# A31G12x register map
Vendor: VENDOR ABOV Semiconductor Co., Ltd.; Series: A31G12x; File version: 1.0
CPU: CM0+ r0p1, little endian, no MPU, no FPU, VTOR, 2 interrupt priority bits
Registers are 32-bit, read-write, reset 0x0 unless marked. A register's access mark holds for its fields unless they carry their own. Offsets are from the block's base; [hi:lo] are bit positions; {n}, {i} and the like mark numbered series.

## ADC — 12 Bit A/D Converter
Base 0x40003000
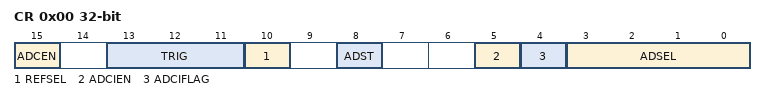
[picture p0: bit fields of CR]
0x00 CR — A/D Converter Control Register
  [15] ADCEN — ADC Module Enable
    0=Disable ADC module operation; 1=Enable ADC module operation
  [13:11] TRIG — ADC Trigger Signal Selection
    0=ADST (Select ADST.); 1=TIMER10 (Select TIMER10 A-Match Signal.); 2=TIMER11 (Select TIMER11 A-Match Signal.); 3=TIMER12 (Select TIMER12 A-Match Signal.); 4=TIMER30 (Select ADC Trigger Signal from TIMER30.)
  [10] REFSEL — ADC Reference Selection
    0=Vdd (Select analog power (VDD).); 1=AVref (Select external reference (AVREF).)
  [8] ADST — ADC Conversion Start
    0=NoEffect; 1=Start (Trigger signal generation for conversion start.)
  [5] ADCIEN — ADC Interrupt Enable
    0=Disable ADC interrupt; 1=Enable ADC interrupt
  [4] ADCIFLAG — ADC Interrupt Flag
    0=No request occurred; 1=Request occurred
  [3:0] ADSEL — A/D Converter Channel Selection
    {v}=AN{v} (Select AN{v}.) (v=0..10); 11=AN11 (Select AN11); 12=AN12 (Select AN12); 13=AN13 (Select AN13)
0x04 DR ro (reset mask 0xFFFFF000) — A/D Converter Data Register
  [11:0] ADDATA — A/D Converter Result Data
0x08 PREDR reset 0xF — A/D Converter Prescaler Data Register
  [4:0] PRED — A/D Converter Prescaler Data

## USART1n — USART 1n (USART + SPI)
Base 0x54000000
Same registers: USART10 0x40003800, USART11 0x40003900, USART12 0x40003A00, USART13 0x40003B00
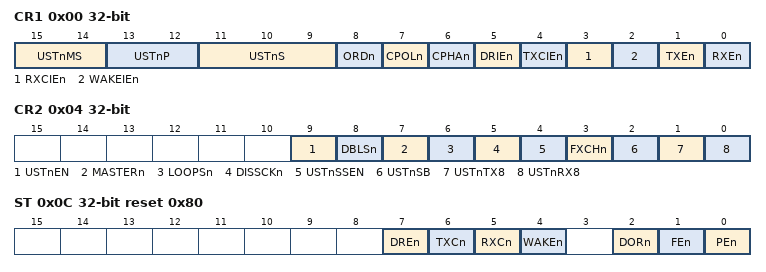
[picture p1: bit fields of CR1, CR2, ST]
0x00 CR1 — USART1n Control Register 1
  [15:14] USTnMS — USART1n Operation Mode Selection
    0=Asynchronous Mode (UART); 1=Synchronous Mode (USRT); 3=SPI (SPI Mode)
  [13:12] USTnP — Selects Parity Generation and Check method (only UART mode)
    0=No (No Parity); 2=Even Parity; 3=Odd (Odd Parity)
  [11:9] USTnS — Selects the length of data bit in a frame when Asynchronous or Synchronous mode
    {v}={v+5}bit (v=0..3); 7=9bit
  [8] ORDn — Selects the first data bit to be transmitted (only SPI mode)
    0=lsbFirst; 1=msbFirst
  [7] CPOLn — Selects the Clock Polarity of ACK in Synchronous or SPI mode
    0=IdleLow (TXD Change @Rising Edge, RXD Change @Falling Edge); 1=IdleHigh (TXD Change @Falling Edge, RXD Change @Rising Edge)
  [6] CPHAn — The CPOLn and this bit determine if data are sampled on the leading or trailing edge of SCK (only SPI mode)
    0=StartIdle (Start with idle state.); 1=StartInverted (Start with inverted idle state.)
  [5] DRIEn — Transmit Data Register Empty Interrupt Enable
  [4] TXCIEn — Transmit Complete Interrupt Enable
  [3] RXCIEn — Receive Complete Interrupt Enable
  [2] WAKEIEn — Asynchronous Wake-Up Interrupt Enable in Deep Sleep Mode
  [1] TXEn — Enable the transmitter unit.
  [0] RXEn — Enable the receiver unit.
0x04 CR2 — USART1n Control Register 2
  [9] USTnEN — Activate USART1n Block
  [8] DBLSn — Selects receiver sampling rate (only UART mode)
  [7] MASTERn — Selects master or slave in SPI1n or Synchronous mode and controls the direction of SCK1n pin
  [6] LOOPSn — Control the Loop Back mode of USART1n for test mode
  [5] DISSCKn — In synchronous mode operation, selects the waveform of SCK1n output
  [4] USTnSSEN — This bit controls the SS1n pin operation (only SPI mode)
  [3] FXCHn — SPI1n port function exchange control (only SPI mode)
  [2] USTnSB — Selects the length of stop bit in Asynchronous or Synchronous mode
  [1] USTnTX8 — The ninth bit of data frame in Asynchronous or Synchronous mode of operation
  [0] USTnRX8 — The ninth bit of data frame in Asynchronous or Synchronous mode of operation
0x0C ST reset 0x80 — USART1n Status Register
  [7] DREn — Transmit Data Register Empty Interrupt Flag
  [6] TXCn — Transmit Complete Interrupt Flag
  [5] RXCn ro — Receive Complete Interrupt Flag
  [4] WAKEn — Asynchronous Wake-Up Interrupt Flag
  [2] DORn ro — This bit is set if data OverRun takes place
  [1] FEn — This bit is set if the first stop bit of next character in the receive buffer is detected as '0'
  [0] PEn — This bit is set if the next character in the receive buffer has a Parity Error while parity is checked
0x10 BDR reset 0xFFF — USART1n Baud Rate Generation Register
  [11:0] BDATA — The value in this register is used to generate internal baud rate in UART mode or to generate SCK clock in SPI mode
0x14 DR — USART1n Data Register
  [7:0] DATA — The USART Transmit buffer and Receive buffer share the same I/O address with this DATA register

## Notices in the file
Copyright (C) 2012 ARM Limited. All rights reserved.
Purpose: System Viewer Description (SVD) Example (Schema Version 1.1)
This is a description of a none-existent and incomplete device
for demonstration purposes only.
Redistribution and use in source and binary forms, with or without
modification, are permitted provided that the following conditions are met:
- Redistributions of source code must retain the above copyright
notice, this list of conditions and the following disclaimer.
- Redistributions in binary form must reproduce the above copyright
notice, this list of conditions and the following disclaimer in the
documentation and/or other materials provided with the distribution.
- Neither the name of ARM nor the names of its contributors may be used
to endorse or promote products derived from this software without
specific prior written permission.
THIS SOFTWARE IS PROVIDED BY THE COPYRIGHT HOLDERS AND CONTRIBUTORS "AS IS"
AND ANY EXPRESS OR IMPLIED WARRANTIES, INCLUDING, BUT NOT LIMITED TO, THE
IMPLIED WARRANTIES OF MERCHANTABILITY AND FITNESS FOR A PARTICULAR PURPOSE
ARE DISCLAIMED. IN NO EVENT SHALL COPYRIGHT HOLDERS AND CONTRIBUTORS BE
LIABLE FOR ANY DIRECT, INDIRECT, INCIDENTAL, SPECIAL, EXEMPLARY, OR
CONSEQUENTIAL DAMAGES (INCLUDING, BUT NOT LIMITED TO, PROCUREMENT OF
SUBSTITUTE GOODS OR SERVICES; LOSS OF USE, DATA, OR PROFITS; OR BUSINESS
INTERRUPTION) HOWEVER CAUSED AND ON ANY THEORY OF LIABILITY, WHETHER IN
CONTRACT, STRICT LIABILITY, OR TORT (INCLUDING NEGLIGENCE OR OTHERWISE)
ARISING IN ANY WAY OUT OF THE USE OF THIS SOFTWARE, EVEN IF ADVISED OF THE
POSSIBILITY OF SUCH DAMAGE.
